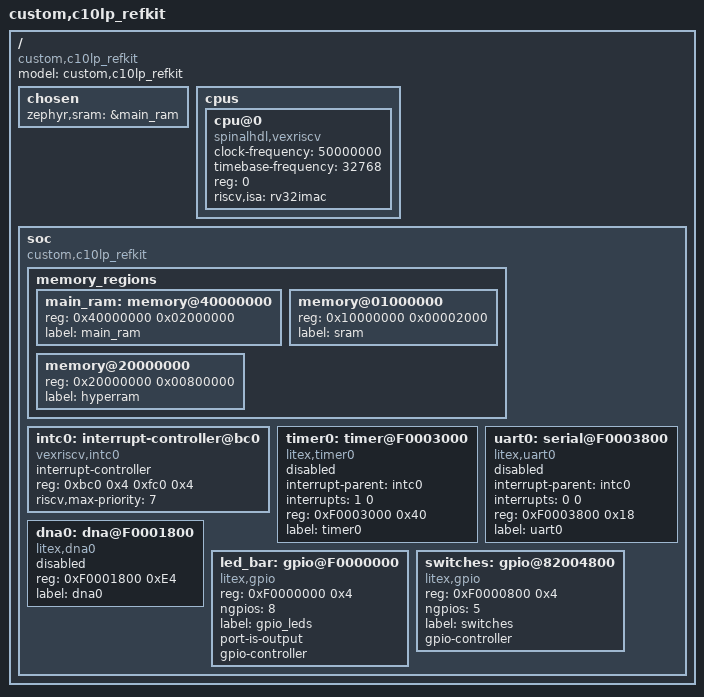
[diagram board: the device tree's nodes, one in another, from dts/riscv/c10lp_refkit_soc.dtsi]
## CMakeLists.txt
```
cmake_minimum_required(VERSION 3.13.1)

list(APPEND BOARD_ROOT "${CMAKE_CURRENT_SOURCE_DIR}/zephyr")
list(APPEND DTS_ROOT "${CMAKE_CURRENT_SOURCE_DIR}/zephyr")

find_package(Zephyr REQUIRED HINTS $ENV{ZEPHYR_BASE})
project(c10lp_refkit_zephyr)

target_sources(
  app
  PRIVATE
    src/main.c
    src/memtest.c
)
```

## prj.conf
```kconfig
CONFIG_GPIO=y
CONFIG_GPIO_LITEX=y

CONFIG_STDOUT_CONSOLE=y
```

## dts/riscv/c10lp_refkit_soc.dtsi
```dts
/ {

  #address-cells = <1>;
  #size-cells = <1>;
  compatible = "custom,c10lp_refkit";
  model = "custom,c10lp_refkit";

  chosen {
    zephyr,sram = &main_ram;
  };

  cpus {
    #address-cells = <1>;
    #size-cells = <0>;
    cpu@0 {
      clock-frequency = <50000000>;
      timebase-frequency = <32768>;
      compatible = "spinalhdl,vexriscv", "riscv";
      device_type = "cpu";
      reg = <0>;
      riscv,isa = "rv32imac";
      status = "okay";
    };
  };

  soc {
    #address-cells = <1>;
    #size-cells = <1>;
    compatible = "custom,c10lp_refkit";
    ranges;

    memory_regions {
      #address-cells = <1>;
      #size-cells = <1>;

      main_ram: memory@40000000 {
        device_type = "memory";
        reg = <0x40000000 0x02000000>;
        label = "main_ram";
      };

      memory@01000000 {
        device_type = "memory";
        reg = <0x10000000 0x00002000>;
        label = "sram";
      };

      memory@20000000 {
        device_type = "memory";
        reg = <0x20000000 0x00800000>;
        label = "hyperram";
      };
    };

    intc0: interrupt-controller@bc0 {
      #interrupt-cells = <2>;
      compatible = "vexriscv,intc0";
      interrupt-controller;
      reg = <0xbc0 0x4 0xfc0 0x4>;
      reg-names = "irq_mask", "irq_pending";
      riscv,max-priority = <7>;
    };

    timer0: timer@F0003000 {
      compatible = "litex,timer0";
      interrupt-parent = <&intc0>;
      interrupts = <1 0>;
      reg = <0xF0003000 0x40>;
      reg-names = "control";
      label = "timer0";
      status = "disabled";
    };

    uart0: serial@F0003800 {
      compatible="litex,uart0";
      interrupt-parent = <&intc0>;
      interrupts = <0 0>;
      reg = <0xF0003800 0x18>;
      reg-names = "control";
      label = "uart0";
      status = "disabled";
    };

    dna0: dna@F0001800 {
      compatible = "litex,dna0";
      reg = <0xF0001800 0xE4>;
      reg-names = "mem";
      label = "dna0";
      status = "disabled";
    };

    led_bar: gpio@F0000000 {
      compatible = "litex,gpio";
      reg = <0xF0000000 0x4>;
      reg-names = "control";
      ngpios = <8>;
      label = "gpio_leds";
      port-is-output;
      gpio-controller;
      #gpio-cells = <2>;
      status = "okay";
    };

    switches: gpio@82004800 {
      compatible = "litex,gpio";
      reg = <0xF0000800 0x4>;
      reg-names = "control";
      ngpios = <5>;
      label = "switches";
      gpio-controller;
      #gpio-cells = <2>;
      status = "okay";
    };

  };

};
```

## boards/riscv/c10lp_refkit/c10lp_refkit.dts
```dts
/dts-v1/;

#include <c10lp_refkit_soc.dtsi>

/ {

  model = "Cyclone 10 LP RefKit development board";
  compatible = "custom,c10lp_refkit";

  chosen {
    zephyr,console = &uart0;
    zephyr,shell-uart = &uart0;
    zephyr,sram = &ram0;
  };

};

&dna0 {
  status = "okay";
};

&uart0 {
  status = "okay";
  current-speed = <115200>;
};

&timer0 {
  status = "okay";
};
```

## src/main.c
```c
#include <zephyr.h>
#include <stdio.h>
#include <drivers/gpio.h>
#include <drivers/hwinfo.h>

#include <zephyr.h>
#include "memtest.h"

#define HWINFO_NODE DT_NODELABEL(dna0)
#define LED_BAR_NODE DT_NODELABEL(led_bar)
#define SWITCHES_NODE DT_NODELABEL(switches)

/*
 * Hardware info
 */
#if !DT_NODE_HAS_STATUS(HWINFO_NODE, okay)

#error "Could not find hwinfo in device tree"

#endif  // if DT_NODE_HAS_STATUS(HWINFO_NODE, okay)

/*
 * LED bar
 */
#if DT_NODE_HAS_STATUS(LED_BAR_NODE, okay)

#define LED_BAR_LABEL DT_LABEL(LED_BAR_NODE)
#define LED_BAR_NGPIOS DT_PROP(LED_BAR_NODE, ngpios)

#else  // DT_NODE_HAS_STATUS(LED_BAR_NODE, okay)

#error "Could not find led bar in device tree"
#define LED_BAR_LABEL ""
#define LED_BAR_NGPIOS 0

#endif  // DT_NODE_HAS_STATUS(LED_BAR_NODE, okay)

/*
 * Switches
 */
#if DT_NODE_HAS_STATUS(SWITCHES_NODE, okay)

#define SWITCHES_LABEL DT_LABEL(SWITCHES_NODE)
#define SWITCHES_NGPIOS DT_PROP(SWITCHES_NODE, ngpios)

#else  // DT_NODE_HAS_STATUS(SWITCHES_NODE, okay)

#error "Could not find switches in device tree"
#define SWITCHES_LABEL ""
#define SWITCHES_NGPIOS 0

#endif  // DT_NODE_HAS_STATUS(SWITCHES_NODE, okay)

void print_hwinfo();

const struct device* init_led_bar();
const struct device* init_switches();

void main(void)
{
  print_hwinfo();
  memtest();

  const struct device* led_bar_dev = init_led_bar();
  const struct device* switches_dev = init_switches();

  const gpio_port_pins_t led_bar_port_mask = BIT_MASK(8);
  const gpio_port_value_t led_bar_pattern = BIT_MASK(4);
  int led_bar_cnt = 0;

  gpio_port_value_t last_switches = 0;

  /*
   * Main loop
   */
  struct k_timer timer;
  k_timer_init(&timer, NULL, NULL);

  k_timer_start(&timer, K_MSEC(100), K_MSEC(100));
  while (1)
  {
    k_timer_status_sync(&timer);

    // React to switches
    gpio_port_value_t switches;
    gpio_port_get(switches_dev, &switches);

    gpio_port_value_t switches_switched = switches ^ last_switches;
    if (switches_switched != 0)
    {
      for (int i = 0; i < SWITCHES_NGPIOS; ++i)
      {
        if (switches_switched & BIT(i))
        {
          if (switches & BIT(i))
          {
            printf("Switch %d pressed\n", i);
          }
          else
          {
            printf("Switch %d released\n", i);
          }
        }
      }
    }

    last_switches = switches;

    // Animate led bar
    gpio_port_set_masked(led_bar_dev, led_bar_port_mask,
                         (led_bar_pattern << led_bar_cnt) |
                             (led_bar_pattern >>
                              (8 - led_bar_cnt)));  // rotating left-shift

    led_bar_cnt++;
    if (led_bar_cnt >= LED_BAR_NGPIOS)
    {
      led_bar_cnt = 0;
    }
  }
}

void print_hwinfo()
{
  const size_t buf_len = DT_PROP_BY_IDX(HWINFO_NODE, reg, 1) / sizeof(uint32_t);
  uint8_t buf[buf_len + 1];

  ssize_t ret = hwinfo_get_device_id(buf, buf_len);
  if (ret < 0)
  {
    printf("Error while reading hardware info: %d\n", ret);
    return;
  }
  else
  {
    buf[ret] = 0;
    printf("Hardware info: %s [%d/%d]\n", buf, ret, buf_len);
  }
}

const struct device* init_led_bar()
{
  const struct device* led_bar_dev = device_get_binding(LED_BAR_LABEL);
  if (led_bar_dev == NULL)
  {
    printf("Could not get binding for device %s\n", LED_BAR_LABEL);
    return NULL;
  }
  else
  {
    printf("Successfully got binding for device %s\n", LED_BAR_LABEL);
  }

  for (int i = 0; i < LED_BAR_NGPIOS; ++i)
  {
    int ret =
        gpio_pin_configure(led_bar_dev, i, GPIO_OUTPUT | GPIO_ACTIVE_HIGH);
    if (ret < 0)
    {
      printf("Error while initializing led bar pin %d: %d\n", i, ret);
      return NULL;
    }
    else
    {
      printf("Successfully initialized led bar pin %d\n", i);
    }
  }

  return led_bar_dev;
}

const struct device* init_switches()
{
  const struct device* switches_dev = device_get_binding(SWITCHES_LABEL);
  if (switches_dev == NULL)
  {
    printf("Could not get binding for device %s\n", SWITCHES_LABEL);
    return NULL;
  }
  else
  {
    printf("Successfully got binding for device %s\n", SWITCHES_LABEL);
  }

  for (int i = 0; i < SWITCHES_NGPIOS; ++i)
  {
    int ret = gpio_pin_configure(switches_dev, i, GPIO_INPUT | GPIO_ACTIVE_LOW);
    if (ret < 0)
    {
      printf("Error while initializing switch %d: %d\n", i, ret);
      return NULL;
    }
    else
    {
      printf("Successfully initialized switch %d\n", i);
    }
  }

  return switches_dev;
}
```

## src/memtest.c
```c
#include "memtest.h"

#include <stdio.h>
#include <zephyr.h>

#define MEMORY_REGIONS_NODE DT_PATH(soc, memory_regions)
#define MEMORY_REGION_LIST(node_id)                                            \
  { DT_LABEL(node_id), DT_REG_ADDR(node_id), DT_REG_SIZE(node_id) },

#define ZEPHYR_SRAM_NODE DT_CHOSEN(zephyr_sram)

struct memory_region
{
  const char* name;
  size_t addr;
  size_t size;
};

const struct memory_region memory_regions[] = { DT_FOREACH_CHILD(
    MEMORY_REGIONS_NODE, MEMORY_REGION_LIST) };

void memtest()
{
  printf("\nRunning memtest...\n");

  size_t num_memory_regions =
      sizeof(memory_regions) / sizeof(struct memory_region);
  for (size_t i = 0; i < num_memory_regions; ++i)
  {
    if (memory_regions[i].addr == DT_REG_ADDR(ZEPHYR_SRAM_NODE))
    {
      printf("[%zu/%zu] (Skipping sram %s used by Zephyr)\n", i,
             num_memory_regions, memory_regions[i].name);
      continue;
    }

    printf("[%zu/%zu] Checking region %s at 0x%08x with size 0x%x\n", i,
           num_memory_regions, memory_regions[i].name, memory_regions[i].addr,
           memory_regions[i].size);

    volatile size_t* test_base = (void*)memory_regions[i].addr;
    const size_t test_num = memory_regions[i].size / sizeof(size_t);

    printf("      Writing increasing counter...     0%%");
    for (size_t i = 0; i < test_num; ++i)
    {
      test_base[i] = i;
      if ((i % 256) == 0)
      {
        printf("\b\b\b\b%3d%%", i * 100 / test_num);
      }
    }
    printf("\b\b\b\b100%%\n");

    printf("      Checking increasing counter...    0%%");
    for (size_t i = 0; i < test_num; ++i)
    {
      size_t test_val = test_base[i];
      if (test_val != i)
      {
        printf("\nERROR! Incorrect value %zu at address 0x%08x (index %zu), "
               "expected %zu\n\n",
               test_val, (size_t)&test_base[i], i, i);
        return;
      }

      if ((i % 256) == 0)
      {
        printf("\b\b\b\b%3d%%", i * 100 / test_num);
      }
    }
    printf("\b\b\b\b100%%\n");
  }

  printf("...done\n\n");
}
```

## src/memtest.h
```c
#ifndef C10LP_REFKIT_ZEPHYR_MEMTEST_H
#define C10LP_REFKIT_ZEPHYR_MEMTEST_H

#include <zephyr.h>

void memtest();

#endif  // ifndef C10LP_REFKIT_ZEPHYR_MEMTEST_H
```
